# UPD70F3508 register map
Vendor: Renesas; Series: V850E2/Px4; File version: 1.0
CPU: other r0p0, little endian, no MPU, FPU, 4 interrupt priority bits
Registers are 8-bit, read-write, reset 0x0 unless marked. A register's access mark holds for its fields unless they carry their own. Offsets are from the block's base; [hi:lo] are bit positions.

## TSG20 — TSG2 Three-phase PWM Timer 0 (Section 15)
Base 0xFF82E200
0x00 TS0IOC0 reset 0x7E — TSG2n I/O Control Register 0
  [6:1] TS0TOE6_1 — Enables/disables writing to TSnIOC2 for outputs TSG2nO6 to TSG2nO1 (bit per output)
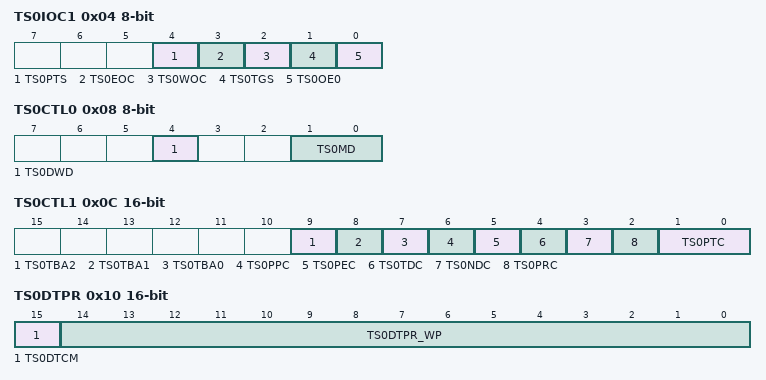
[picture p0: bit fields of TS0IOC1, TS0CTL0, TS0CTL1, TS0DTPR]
0x04 TS0IOC1 — TSG2n I/O Control Register 1
  [4] TS0PTS — Enables/disables edge detection signal (TSnPTE) and two-phase encoder count (TSnPEC) output
  [3] TS0EOC — Enables/disables error interrupt (INTTSG2nIER) detection
  [2] TS0WOC — Enables/disables warning interrupt (INTTSG2nIWN) detection
  [1] TS0TGS — Enables/disables diagnostic output
  [0] TS0OE0 — Enables/disables TSG2nO0 output
0x08 TS0CTL0 — TSG2n Control Register 0
  [4] TS0DWD — Selects the pulse width for the diagnostic output (0: 8 clocks, 1: 16 clocks)
  [1:0] TS0MD — Selects timer mode (00: PWM, 01: HT-PWM, 10: SP-PWM, 11: 120-DC)
0x0C TS0CTL1 16-bit — TSG2n Control Register 1
  [9] TS0TBA2 — Enables/disables simultaneous active state detection of TSG2nO5 and TSG2nO6
  [8] TS0TBA1 — Enables/disables simultaneous active state detection of TSG2nO3 and TSG2nO4
  [7] TS0TBA0 — Enables/disables simultaneous active state detection of TSG2nO1 and TSG2nO2
  [6] TS0PPC — Enables/disables pattern change detection interrupt (INTTSG2nIPC)
  [5] TS0PEC — Enables/disables two-phase encoder count interrupt (INTTSG2nIPEC)
  [4] TS0TDC — Enables/disables dead time compare error interrupt (INTTSG2nIDT)
  [3] TS0NDC — Enables/disables negative-side dead time compare error interrupt
  [2] TS0PRC — Enables/disables PWM output reload complete interrupt (INTTSG2nIPRC)
  [1:0] TS0PTC — Selects operation after detection of pattern change (PTC[1:0])
0x10 TS0DTPR 16-bit — TSG2n Dead Time Protection Register
  [15] TS0DTCM — Dead time register write protection (0: enable rewrite, 1: disable rewrite)
  [14:0] TS0DTPR_WP — Write protection code (0000H to 7FFFH)
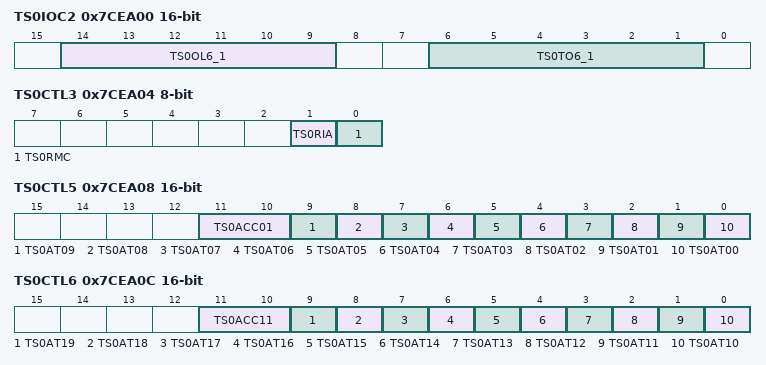
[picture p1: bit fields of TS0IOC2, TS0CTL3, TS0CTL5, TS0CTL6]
0x7CEA00 TS0IOC2 16-bit — TSG2n I/O Control Register 2
  [14:9] TS0OL6_1 — Active level for TSG2nO6 to TSG2nO1 (0: high, 1: low; one bit per output)
  [6:1] TS0TO6_1 — Latch level of output buffer for TSG2nO6 to TSG2nO1 (one bit per output)
0x7CEA04 TS0CTL3 — TSG2n Control Register 3
  [1] TS0RIA — Selects reload timing (0: peak/valley reload, 1: peak/valley interrupt)
  [0] TS0RMC — Selects compare register transfer timing (0: reload mode, 1: anytime rewrite)
0x7CEA08 TS0CTL5 16-bit — TSG2n Control Register 5
  [11:10] TS0ACC01 — Skipping rate for A/D trigger TSnADTRG0 (00: none, 01: 1/2, 10: 1/4, 11: 1/8)
  [9] TS0AT09 — Generate TSnADTRG0 at sub-counter peak (HT-PWM peak timing)
  [8] TS0AT08 — Generate TSnADTRG0 at sub-counter valley (HT-PWM valley timing)
  [7] TS0AT07 — Generate TSnADTRG0 at TSnDCMP2 match during decrement
  [6] TS0AT06 — Generate TSnADTRG0 at TSnDCMP2 match during increment
  [5] TS0AT05 — Generate TSnADTRG0 at TSnDCMP1 match during decrement (HT-PWM only)
  [4] TS0AT04 — Generate TSnADTRG0 at TSnDCMP1 match during increment
  [3] TS0AT03 — Generate TSnADTRG0 at TSnDCMP0 match during decrement (HT-PWM only)
  [2] TS0AT02 — Generate TSnADTRG0 at TSnDCMP0 match during increment
  [1] TS0AT01 — Generate TSnADTRG0 at peak interrupt timing
  [0] TS0AT00 — Generate TSnADTRG0 at valley interrupt timing
0x7CEA0C TS0CTL6 16-bit — TSG2n Control Register 6
  [11:10] TS0ACC11 — Skipping rate for A/D trigger TSnADTRG1 (00: none, 01: 1/2, 10: 1/4, 11: 1/8)
  [9] TS0AT19 — Generate TSnADTRG1 at sub-counter peak (HT-PWM peak timing)
  [8] TS0AT18 — Generate TSnADTRG1 at sub-counter valley (HT-PWM valley timing)
  [7] TS0AT17 — Generate TSnADTRG1 at TSnDCMP2 match during decrement
  [6] TS0AT16 — Generate TSnADTRG1 at TSnDCMP2 match during increment
  [5] TS0AT15 — Generate TSnADTRG1 at TSnDCMP1 match during decrement (HT-PWM only)
  [4] TS0AT14 — Generate TSnADTRG1 at TSnDCMP1 match during increment
  [3] TS0AT13 — Generate TSnADTRG1 at TSnDCMP0 match during decrement (HT-PWM only)
  [2] TS0AT12 — Generate TSnADTRG1 at TSnDCMP0 match during increment
  [1] TS0AT11 — Generate TSnADTRG1 at peak interrupt timing
  [0] TS0AT10 — Generate TSnADTRG1 at valley interrupt timing
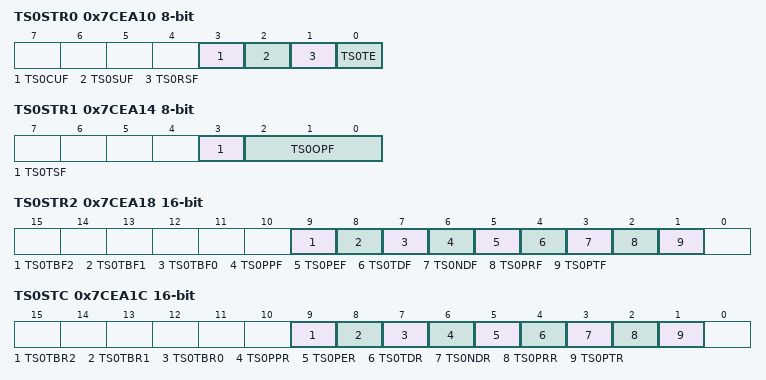
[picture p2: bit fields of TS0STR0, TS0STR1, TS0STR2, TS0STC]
0x7CEA10 TS0STR0 ro — TSG2n Status Register 0
  [3] TS0CUF — Count direction of 16-bit counter (0: incrementing, 1: decrementing; HT-PWM only)
  [2] TS0SUF — Count direction of 16-bit sub-counter (0: incrementing, 1: decrementing; HT-PWM only)
  [1] TS0RSF — Reload request flag (0: no request or complete, 1: pending; reload mode only)
  [0] TS0TE — TSG2n operation status (0: stopped, 1: operating)
0x7CEA14 TS0STR1 ro — TSG2n Status Register 1
  [3] TS0TSF — Pattern change order indicator (0: normal rotation, 1: reverse rotation)
  [2:0] TS0OPF — Output pattern of timer output pins TSG2nO1 to TSG2nO6 (OPF[2:0])
0x7CEA18 TS0STR2 16-bit ro — TSG2n Status Register 2
  [9] TS0TBF2 — Simultaneous active flag for TSG2nO5/TSG2nO6 (0: not simultaneous, 1: simultaneous)
  [8] TS0TBF1 — Simultaneous active flag for TSG2nO3/TSG2nO4
  [7] TS0TBF0 — Simultaneous active flag for TSG2nO1/TSG2nO2
  [6] TS0PPF — Pattern change detection flag
  [5] TS0PEF — Two-phase encoder count signal flag
  [4] TS0TDF — Dead time compare error flag (positive-side)
  [3] TS0NDF — Dead time compare error flag (negative-side)
  [2] TS0PRF — PWM reload complete flag
  [1] TS0PTF — Pattern change complete flag
0x7CEA1C TS0STC 16-bit wo — TSG2n Status Clear Trigger Register
  [9] TS0TBR2 — Clear trigger for TSnSTR2.TSnTBF2
  [8] TS0TBR1 — Clear trigger for TSnSTR2.TSnTBF1
  [7] TS0TBR0 — Clear trigger for TSnSTR2.TSnTBF0
  [6] TS0PPR — Clear trigger for TSnSTR2.TSnPPF
  [5] TS0PER — Clear trigger for TSnSTR2.TSnPEF
  [4] TS0TDR — Clear trigger for TSnSTR2.TSnTDF
  [3] TS0NDR — Clear trigger for TSnSTR2.TSnNDF
  [2] TS0PRR — Clear trigger for TSnSTR2.TSnPRF
  [1] TS0PTR — Clear trigger for TSnSTR2.TSnPTF
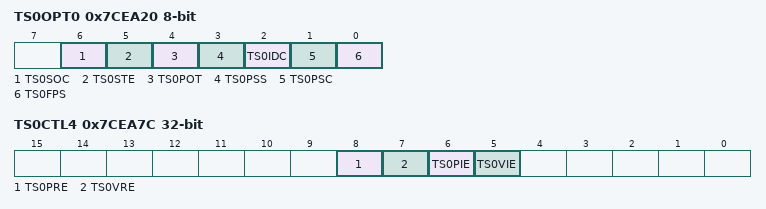
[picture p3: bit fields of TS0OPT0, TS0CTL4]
0x7CEA20 TS0OPT0 — TSG2n Option Register 0
  [6] TS0SOC — Enables/disables software control of timer output (TSG2nO1 to TSG2nO6)
  [5] TS0STE — Enables/disables pattern output trigger (TSG2nPTSI0-2 and TSnOPCI0-1 inputs)
  [4] TS0POT — Selects pattern output trigger (0: external pattern pins, 1: TSnOPCI0/1 edges)
  [3] TS0PSS — Enables pattern output order switch factor by TSnPSC
  [2] TS0IDC — Output pattern order determination factor
  [1] TS0PSC — Pattern output order switch control
  [0] TS0FPS — Selects fixed-pattern output or compare-match output
0x7CEA24 TS0OPT1 — TSG2n Option Register 1
  [2:0] TS0SPC — Timer output pattern for software output/120-DC mode (SPC[2:0])
0x7CEA28 TS0CNT 16-bit ro — TSG2n Counter Read Buffer Register
0x7CEA2C TS0SBC 16-bit ro — TSG2n Sub-Counter Read Buffer Register
0x7CEA30 TS0TRG0 wo — TSG2n Trigger Register 0
  [0] TS0TS — Timer start trigger (1: start/restart timer; always reads 0)
0x7CEA34 TS0TRG1 wo — TSG2n Trigger Register 1
  [0] TS0TT — Timer stop trigger (1: stop timer; always reads 0)
0x7CEA40 TS0CMP1W 32-bit — TSG2n Compare Register 1 and 2 (word)
0x7CEA44 TS0CMP5W 32-bit — TSG2n Compare Register 5 and 6 (word)
0x7CEA48 TS0CMP9W 32-bit — TSG2n Compare Register 9 and 10 (word)
0x7CEA4C TS0CMP3W 32-bit — TSG2n Compare Register 3 and 4 (word)
0x7CEA50 TS0CMP7W 32-bit — TSG2n Compare Register 7 and 8 (word)
0x7CEA54 TS0CMP11W 32-bit — TSG2n Compare Register 11 and 12 (word)
0x7CEA58 TS0CMP0 32-bit — TSG2n Compare Register 0
0x7CEA5C TS0DCMP0W 32-bit — TSG2n Diagnostic Output Compare Register 0 and 1
0x7CEA60 TS0DCMP2 32-bit — TSG2n Diagnostic Output Compare Register 2
0x7CEA64 TS0PAT0W 32-bit — TSG2n Pattern Register 0
0x7CEA68 TS0PAT1W 32-bit — TSG2n Pattern Register 1
0x7CEA6C TS0DTC0W 32-bit — TSG2n Dead Time Setting Register 0
0x7CEA70 TS0DTC1W 32-bit — TSG2n Dead Time Setting Register 1
0x7CEA74 TS0IOC3 32-bit — TSG2n I/O Control Register 3
  [6:1] TS0TOL6_1 — Set/clear level control for TSG2nO6 to TSG2nO1 (0: normal, 1: inverted)
0x7CEA78 TS0CTL2 32-bit — TSG2n Control Register 2
  [0] TS0CKS — Selects count clock (0: PCLK, 1: PCLK gated by TSG2nCLKI)
0x7CEA7C TS0CTL4 32-bit — TSG2n Control Register 4
  [8] TS0PRE — Enables/disables peak reload timing
  [7] TS0VRE — Enables/disables valley reload timing (valid in HT-PWM mode only)
  [6] TS0PIE — Enables/disables peak interrupt (INTTSG2nIPEK) generation
  [5] TS0VIE — Enables/disables valley interrupt (INTTSG2nIVLY) generation (HT-PWM only)
0x7CEA80 TS0CMP1 16-bit — TSG2n Compare Register 1
0x7CEA84 TS0CMP2 16-bit — TSG2n Compare Register 2
0x7CEA88 TS0CMP5 16-bit — TSG2n Compare Register 5
0x7CEA8C TS0CMP6 16-bit — TSG2n Compare Register 6
0x7CEA90 TS0CMP9 16-bit — TSG2n Compare Register 9
0x7CEA94 TS0CMP10 16-bit — TSG2n Compare Register 10
0x7CEA98 TS0CMP3 16-bit — TSG2n Compare Register 3
0x7CEA9C TS0CMP4 16-bit — TSG2n Compare Register 4
0x7CEAA0 TS0CMP7 16-bit — TSG2n Compare Register 7
0x7CEAA4 TS0CMP8 16-bit — TSG2n Compare Register 8
0x7CEAA8 TS0CMP11 16-bit — TSG2n Compare Register 11
0x7CEAAC TS0CMP12 16-bit — TSG2n Compare Register 12
0x7CEAB0 TS0CMPU 16-bit — TSG2n HT-PWM U Phase Compare Register
0x7CEAB4 TS0CMPV 16-bit — TSG2n HT-PWM V Phase Compare Register
0x7CEAB8 TS0CMPW 16-bit — TSG2n HT-PWM W Phase Compare Register
0x7CEABC TS0UPW 16-bit — TSG2n SP-PWM U Phase Active Width Setting Register
0x7CEAC0 TS0VPW 16-bit — TSG2n SP-PWM V Phase Active Width Setting Register
0x7CEAC4 TS0WPW 16-bit — TSG2n SP-PWM W Phase Active Width Setting Register
